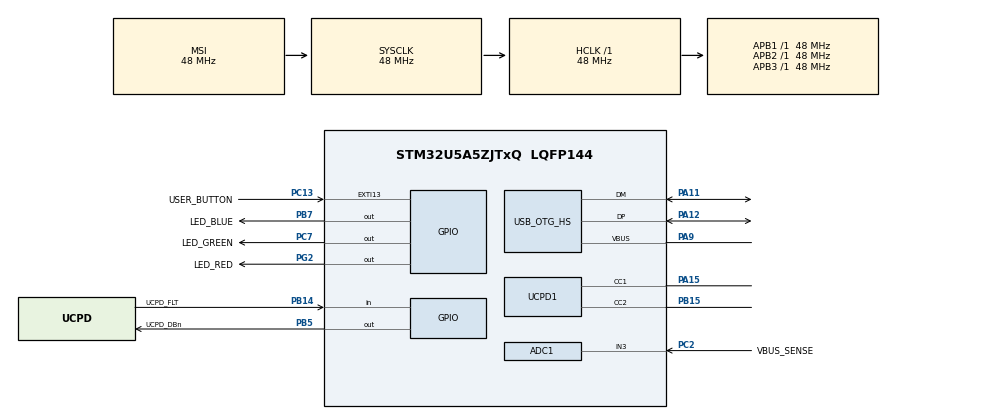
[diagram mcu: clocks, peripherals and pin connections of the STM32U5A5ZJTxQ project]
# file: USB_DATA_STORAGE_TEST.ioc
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ADC1.Channel-1\#ChannelRegularConversion=ADC_CHANNEL_3
ADC1.MonitoredBy-1\#ChannelRegularConversion=__NULL
ADC1.NbrOfConversionFlag=1
ADC1.OffsetNumber-1\#ChannelRegularConversion=ADC_OFFSET_NONE
ADC1.Rank-1\#ChannelRegularConversion=1
ADC1.SamplingTime-1\#ChannelRegularConversion=ADC_SAMPLETIME_5CYCLE
ADC1.master=1
CORTEX_M33_NS.userName=CORTEX_M33
FILEX.FX_ENABLE_EXFAT=1
Mcu.Family=STM32U5
Mcu.Name=STM32U5A5ZJTxQ
Mcu.Package=LQFP144
NVIC.OTG_HS_IRQn=true\:0\:0\:false\:false\:true\:true\:true\:true
NVIC.PriorityGroup=NVIC_PRIORITYGROUP_4
PA11.Mode=Internal_Phy_Host
PA11.Signal=USB_OTG_HS_DM
PA12.Mode=Internal_Phy_Host
PA12.Signal=USB_OTG_HS_DP
PA13\ (JTMS/SWDIO).Signal=DEBUG_JTMS-SWDIO
PA14\ (JTCK/SWCLK).Signal=DEBUG_JTCK-SWCLK
PA15\ (JTDI).Mode=Sink_AllSignals
PA15\ (JTDI).Signal=UCPD1_CC1
PA9.Mode=Activate_VBUS_FS
PA9.Signal=USB_OTG_HS_VBUS
PB14.GPIO_Label=UCPD_FLT
PB14.Signal=GPIO_Input
PB15.Mode=Sink_AllSignals
PB15.Signal=UCPD1_CC2
PB3\ (JTDO/TRACESWO).Signal=DEBUG_JTDO-SWO
PB5.GPIO_Label=UCPD_DBn
PB5.Signal=GPIO_Output
PB7.GPIO_Label=LED_BLUE
PB7.Signal=GPIO_Output
PC13.GPIO_Label=USER_BUTTON
PC13.Signal=GPXTI13
PC14-OSC32_IN\ (PC14).Mode=LSE-External-Oscillator
PC14-OSC32_IN\ (PC14).Signal=RCC_OSC32_IN
PC15-OSC32_OUT\ (PC15).Mode=LSE-External-Oscillator
PC15-OSC32_OUT\ (PC15).Signal=RCC_OSC32_OUT
PC2.GPIO_Label=VBUS_SENSE
PC2.Mode=IN3-Single-Ended
PC2.Signal=ADC1_IN3
PC7.GPIO_Label=LED_GREEN
PC7.Signal=GPIO_Output
PG2.GPIO_Label=LED_RED
PG2.Signal=GPIO_Output
PH0-OSC_IN\ (PH0).Mode=HSE-External-Oscillator
PH0-OSC_IN\ (PH0).Signal=RCC_OSC_IN
PH1-OSC_OUT\ (PH1).Mode=HSE-External-Oscillator
PH1-OSC_OUT\ (PH1).Signal=RCC_OSC_OUT
ProjectManager.HeapSize=0x200
ProjectManager.StackSize=0x400
ProjectManager.TargetToolchain=STM32CubeIDE
RCC.ADCFreq_Value=16000000
RCC.AHBFreq_Value=48000000
RCC.APB1Freq_Value=48000000
RCC.APB1TimFreq_Value=48000000
RCC.APB2Freq_Value=48000000
RCC.APB2TimFreq_Value=48000000
RCC.APB3Freq_Value=48000000
RCC.CortexFreq_Value=48000000
RCC.DACCLockSelectionVirtual=RCC_DAC1CLKSOURCE_LSI
RCC.EPOD_VALUE=48000000
RCC.HCLKFreq_Value=48000000
RCC.HSE_VALUE=16000000
RCC.HSI48_VALUE=48000000
RCC.HSI_VALUE=16000000
RCC.LSIDIV_VALUE=32000
RCC.MSIClockRange=RCC_MSIRANGE_0
RCC.MSI_VALUE=48000000
RCC.PLL1P=8
RCC.PLLFRACN=0
RCC.PLLM=3
RCC.PLLN=8
RCC.SYSCLKFreq_VALUE=48000000
RCC.VCOOutputFreq_Value=128000000
USB_OTG_HS.VirtualMode=Host_HS
VP_FILEX_VS_FileOoSystemJjFileXJjCore.Mode=FileX_Core
VP_ICACHE_VS_ICACHE.Mode=DirectMappedCache
VP_LPBAMQUEUE_VS_QUEUE.Mode=QUEUEMODE
VP_LPBAM_VS_SIG1.Mode=SmartRun
VP_LPBAM_VS_SIG4.Mode=LPDMA1
VP_MEMORYMAP_VS_MEMORYMAP.Mode=CurAppReg
VP_PWR_VS_DBSignals.Mode=DisableDeadBatterySignals
VP_PWR_VS_LPOM.Mode=PowerOptimisation
VP_PWR_VS_SECSignals.Mode=Security/Privilege
VP_PWR_Vdda.Mode=isolationVdda
board=NUCLEO-U5A5ZJ-Q

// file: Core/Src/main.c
/* USER CODE BEGIN Header */
/**
  ******************************************************************************
  * @file           : main.c
  * @brief          : Main program body
  ******************************************************************************
  * @attention
  *
  * Copyright (c) 2023 STMicroelectronics.
  * All rights reserved.
  *
  * This software is licensed under terms that can be found in the LICENSE file
  * in the root directory of this software component.
  * If no LICENSE file comes with this software, it is provided AS-IS.
  *
  ******************************************************************************
  */
/* USER CODE END Header */
#include "main.h"
#include "app_filex.h"
#include "usb_host.h"

ADC_HandleTypeDef hadc1;

HCD_HandleTypeDef hhcd_USB_OTG_HS;

void SystemClock_Config(void);
static void MX_GPIO_Init(void);
static void MX_ICACHE_Init(void);
static void MX_UCPD1_Init(void);
static void MX_USB_OTG_HS_HCD_Init(void);
static void MX_ADC1_Init(void);
static void MX_MEMORYMAP_Init(void);

void MX_USB_HOST_Process(void);

int main(void)
{

  /* MCU Configuration--------------------------------------------------------*/

  /* Reset of all peripherals, Initializes the Flash interface and the Systick. */
  HAL_Init();

  /* Configure the system clock */
  SystemClock_Config();

  /* Initialize all configured peripherals */
  MX_GPIO_Init();
  MX_ICACHE_Init();
  MX_UCPD1_Init();
  MX_USB_OTG_HS_HCD_Init();
  MX_ADC1_Init();
  MX_FileX_Init();
  MX_MEMORYMAP_Init();
  /* USER CODE BEGIN 2 */
  MX_USB_HOST_Init();
  /* USER CODE END 2 */

  /* Infinite loop */
  while (1)
  {
	  MX_USB_HOST_Process();
  }
}

void SystemClock_Config(void)
{
  RCC_OscInitTypeDef RCC_OscInitStruct = {0};
  RCC_ClkInitTypeDef RCC_ClkInitStruct = {0};

  /** Configure the main internal regulator output voltage
  */
  if (HAL_PWREx_ControlVoltageScaling(PWR_REGULATOR_VOLTAGE_SCALE3) != HAL_OK)
  {
    Error_Handler();
  }

  /** Initializes the CPU, AHB and APB buses clocks
  */
  RCC_OscInitStruct.OscillatorType = RCC_OSCILLATORTYPE_HSI|RCC_OSCILLATORTYPE_MSI;
  RCC_OscInitStruct.HSIState = RCC_HSI_ON;
  RCC_OscInitStruct.HSICalibrationValue = RCC_HSICALIBRATION_DEFAULT;
  RCC_OscInitStruct.MSIState = RCC_MSI_ON;
  RCC_OscInitStruct.MSICalibrationValue = RCC_MSICALIBRATION_DEFAULT;
  RCC_OscInitStruct.MSIClockRange = RCC_MSIRANGE_0;
  RCC_OscInitStruct.PLL.PLLState = RCC_PLL_ON;
  RCC_OscInitStruct.PLL.PLLSource = RCC_PLLSOURCE_MSI;
  RCC_OscInitStruct.PLL.PLLMBOOST = RCC_PLLMBOOST_DIV4;
  RCC_OscInitStruct.PLL.PLLM = 3;
  RCC_OscInitStruct.PLL.PLLN = 8;
  RCC_OscInitStruct.PLL.PLLP = 8;
  RCC_OscInitStruct.PLL.PLLQ = 2;
  RCC_OscInitStruct.PLL.PLLR = 2;
  RCC_OscInitStruct.PLL.PLLRGE = RCC_PLLVCIRANGE_1;
  RCC_OscInitStruct.PLL.PLLFRACN = 0;
  if (HAL_RCC_OscConfig(&RCC_OscInitStruct) != HAL_OK)
  {
    Error_Handler();
  }

  /** Initializes the CPU, AHB and APB buses clocks
  */
  RCC_ClkInitStruct.ClockType = RCC_CLOCKTYPE_HCLK|RCC_CLOCKTYPE_SYSCLK
                              |RCC_CLOCKTYPE_PCLK1|RCC_CLOCKTYPE_PCLK2
                              |RCC_CLOCKTYPE_PCLK3;
  RCC_ClkInitStruct.SYSCLKSource = RCC_SYSCLKSOURCE_MSI;
  RCC_ClkInitStruct.AHBCLKDivider = RCC_SYSCLK_DIV1;
  RCC_ClkInitStruct.APB1CLKDivider = RCC_HCLK_DIV1;
  RCC_ClkInitStruct.APB2CLKDivider = RCC_HCLK_DIV1;
  RCC_ClkInitStruct.APB3CLKDivider = RCC_HCLK_DIV1;

  if (HAL_RCC_ClockConfig(&RCC_ClkInitStruct, FLASH_LATENCY_1) != HAL_OK)
  {
    Error_Handler();
  }
}

static void MX_ADC1_Init(void)
{

  ADC_ChannelConfTypeDef sConfig = {0};

  /** Common config
  */
  hadc1.Instance = ADC1;
  hadc1.Init.ClockPrescaler = ADC_CLOCK_ASYNC_DIV1;
  hadc1.Init.Resolution = ADC_RESOLUTION_14B;
  hadc1.Init.GainCompensation = 0;
  hadc1.Init.DataAlign = ADC_DATAALIGN_RIGHT;
  hadc1.Init.ScanConvMode = ADC_SCAN_DISABLE;
  hadc1.Init.EOCSelection = ADC_EOC_SINGLE_CONV;
  hadc1.Init.LowPowerAutoWait = DISABLE;
  hadc1.Init.ContinuousConvMode = DISABLE;
  hadc1.Init.NbrOfConversion = 1;
  hadc1.Init.DiscontinuousConvMode = DISABLE;
  hadc1.Init.ExternalTrigConv = ADC_SOFTWARE_START;
  hadc1.Init.ExternalTrigConvEdge = ADC_EXTERNALTRIGCONVEDGE_NONE;
  hadc1.Init.DMAContinuousRequests = DISABLE;
  hadc1.Init.TriggerFrequencyMode = ADC_TRIGGER_FREQ_HIGH;
  hadc1.Init.Overrun = ADC_OVR_DATA_PRESERVED;
  hadc1.Init.LeftBitShift = ADC_LEFTBITSHIFT_NONE;
  hadc1.Init.ConversionDataManagement = ADC_CONVERSIONDATA_DR;
  hadc1.Init.OversamplingMode = DISABLE;
  if (HAL_ADC_Init(&hadc1) != HAL_OK)
  {
    Error_Handler();
  }

  /** Configure Regular Channel
  */
  sConfig.Channel = ADC_CHANNEL_3;
  sConfig.Rank = ADC_REGULAR_RANK_1;
  sConfig.SamplingTime = ADC_SAMPLETIME_5CYCLE;
  sConfig.SingleDiff = ADC_SINGLE_ENDED;
  sConfig.OffsetNumber = ADC_OFFSET_NONE;
  sConfig.Offset = 0;
  if (HAL_ADC_ConfigChannel(&hadc1, &sConfig) != HAL_OK)
  {
    Error_Handler();
  }

}

static void MX_ICACHE_Init(void)
{

  /** Enable instruction cache in 1-way (direct mapped cache)
  */
  if (HAL_ICACHE_ConfigAssociativityMode(ICACHE_1WAY) != HAL_OK)
  {
    Error_Handler();
  }
  if (HAL_ICACHE_Enable() != HAL_OK)
  {
    Error_Handler();
  }

}

static void MX_MEMORYMAP_Init(void)
{

}

static void MX_UCPD1_Init(void)
{

  LL_GPIO_InitTypeDef GPIO_InitStruct = {0};

  /* Peripheral clock enable */
  LL_APB1_GRP2_EnableClock(LL_APB1_GRP2_PERIPH_UCPD1);

  LL_AHB2_GRP1_EnableClock(LL_AHB2_GRP1_PERIPH_GPIOB);
  LL_AHB2_GRP1_EnableClock(LL_AHB2_GRP1_PERIPH_GPIOA);
  /**UCPD1 GPIO Configuration
  PB15   ------> UCPD1_CC2
  PA15 (JTDI)   ------> UCPD1_CC1
  */
  GPIO_InitStruct.Pin = LL_GPIO_PIN_15;
  GPIO_InitStruct.Mode = LL_GPIO_MODE_ANALOG;
  GPIO_InitStruct.Pull = LL_GPIO_PULL_NO;
  LL_GPIO_Init(GPIOB, &GPIO_InitStruct);

  GPIO_InitStruct.Pin = LL_GPIO_PIN_15;
  GPIO_InitStruct.Mode = LL_GPIO_MODE_ANALOG;
  GPIO_InitStruct.Pull = LL_GPIO_PULL_NO;
  LL_GPIO_Init(GPIOA, &GPIO_InitStruct);

}

static void MX_USB_OTG_HS_HCD_Init(void)
{

  hhcd_USB_OTG_HS.Instance = USB_OTG_HS;
  hhcd_USB_OTG_HS.Init.Host_channels = 16;
  hhcd_USB_OTG_HS.Init.speed = HCD_SPEED_HIGH;
  hhcd_USB_OTG_HS.Init.dma_enable = DISABLE;
  hhcd_USB_OTG_HS.Init.phy_itface = USB_OTG_HS_EMBEDDED_PHY;
  hhcd_USB_OTG_HS.Init.Sof_enable = DISABLE;
  hhcd_USB_OTG_HS.Init.low_power_enable = DISABLE;
  hhcd_USB_OTG_HS.Init.use_external_vbus = ENABLE;
  if (HAL_HCD_Init(&hhcd_USB_OTG_HS) != HAL_OK)
  {
    Error_Handler();
  }

}

static void MX_GPIO_Init(void)
{
  GPIO_InitTypeDef GPIO_InitStruct = {0};

  /* GPIO Ports Clock Enable */
  __HAL_RCC_GPIOC_CLK_ENABLE();
  __HAL_RCC_GPIOH_CLK_ENABLE();
  __HAL_RCC_GPIOB_CLK_ENABLE();
  __HAL_RCC_GPIOG_CLK_ENABLE();
  __HAL_RCC_GPIOA_CLK_ENABLE();

  /*Configure GPIO pin Output Level */
  HAL_GPIO_WritePin(LED_RED_GPIO_Port, LED_RED_Pin, GPIO_PIN_RESET);

  /*Configure GPIO pin Output Level */
  HAL_GPIO_WritePin(LED_GREEN_GPIO_Port, LED_GREEN_Pin, GPIO_PIN_RESET);

  /*Configure GPIO pin Output Level */
  HAL_GPIO_WritePin(GPIOB, UCPD_DBn_Pin|LED_BLUE_Pin, GPIO_PIN_RESET);

  /*Configure GPIO pin : USER_BUTTON_Pin */
  GPIO_InitStruct.Pin = USER_BUTTON_Pin;
  GPIO_InitStruct.Mode = GPIO_MODE_IT_RISING;
  GPIO_InitStruct.Pull = GPIO_NOPULL;
  HAL_GPIO_Init(USER_BUTTON_GPIO_Port, &GPIO_InitStruct);

  /*Configure GPIO pin : UCPD_FLT_Pin */
  GPIO_InitStruct.Pin = UCPD_FLT_Pin;
  GPIO_InitStruct.Mode = GPIO_MODE_INPUT;
  GPIO_InitStruct.Pull = GPIO_NOPULL;
  HAL_GPIO_Init(UCPD_FLT_GPIO_Port, &GPIO_InitStruct);

  /*Configure GPIO pin : LED_RED_Pin */
  GPIO_InitStruct.Pin = LED_RED_Pin;
  GPIO_InitStruct.Mode = GPIO_MODE_OUTPUT_PP;
  GPIO_InitStruct.Pull = GPIO_NOPULL;
  GPIO_InitStruct.Speed = GPIO_SPEED_FREQ_LOW;
  HAL_GPIO_Init(LED_RED_GPIO_Port, &GPIO_InitStruct);

  /*Configure GPIO pin : LED_GREEN_Pin */
  GPIO_InitStruct.Pin = LED_GREEN_Pin;
  GPIO_InitStruct.Mode = GPIO_MODE_OUTPUT_PP;
  GPIO_InitStruct.Pull = GPIO_NOPULL;
  GPIO_InitStruct.Speed = GPIO_SPEED_FREQ_LOW;
  HAL_GPIO_Init(LED_GREEN_GPIO_Port, &GPIO_InitStruct);

  /*Configure GPIO pins : UCPD_DBn_Pin LED_BLUE_Pin */
  GPIO_InitStruct.Pin = UCPD_DBn_Pin|LED_BLUE_Pin;
  GPIO_InitStruct.Mode = GPIO_MODE_OUTPUT_PP;
  GPIO_InitStruct.Pull = GPIO_NOPULL;
  GPIO_InitStruct.Speed = GPIO_SPEED_FREQ_LOW;
  HAL_GPIO_Init(GPIOB, &GPIO_InitStruct);

}

void Error_Handler(void)
{
  __disable_irq();
  while (1)
  {
  }
}
